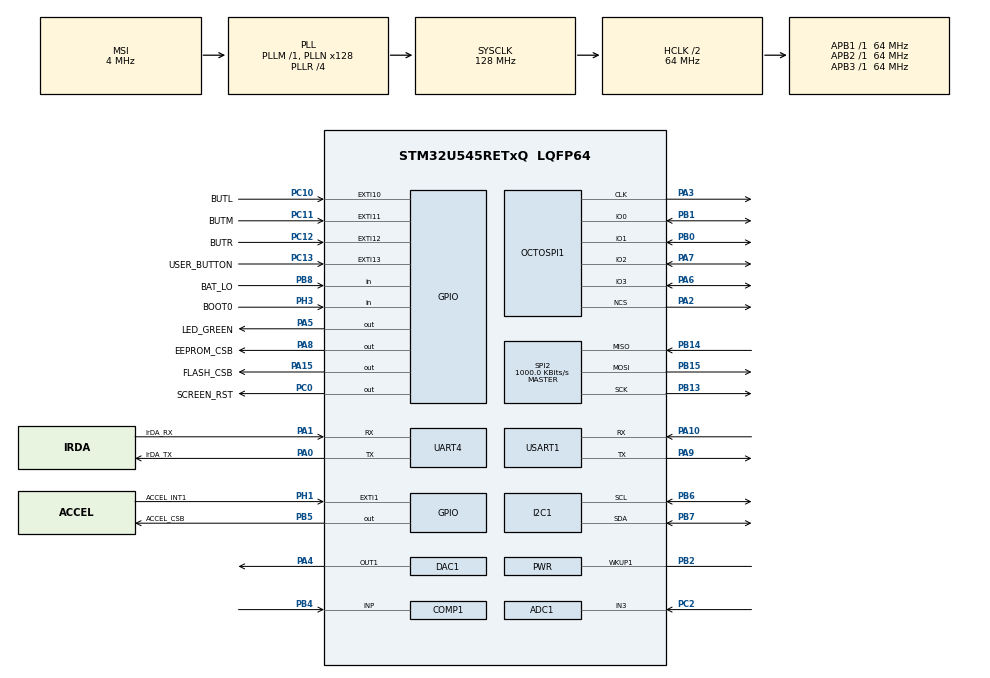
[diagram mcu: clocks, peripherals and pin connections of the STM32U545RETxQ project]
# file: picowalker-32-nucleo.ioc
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ADC1.Channel-1\#ChannelRegularConversion=ADC_CHANNEL_3
ADC1.MonitoredBy-1\#ChannelRegularConversion=__NULL
ADC1.NbrOfConversionFlag=1
ADC1.OffsetNumber-1\#ChannelRegularConversion=ADC_OFFSET_NONE
ADC1.Rank-1\#ChannelRegularConversion=1
ADC1.SamplingTime-1\#ChannelRegularConversion=ADC_SAMPLETIME_5CYCLE
ADC1.master=1
CORTEX_M33_NS.userName=CORTEX_M33
DAC1.DAC_Channel-DAC_OUT1=DAC_CHANNEL_1
I2C1.Timing=0x10707DBC
Mcu.Family=STM32U5
Mcu.Name=STM32U545RETxQ
Mcu.Package=LQFP64
NVIC.EXTI10_IRQn=true\:0\:0\:false\:false\:true\:true\:true\:true
NVIC.EXTI11_IRQn=true\:0\:0\:false\:false\:true\:true\:true\:true
NVIC.EXTI12_IRQn=true\:0\:0\:false\:false\:true\:true\:true\:true
NVIC.EXTI13_IRQn=true\:0\:0\:false\:false\:true\:true\:true\:true
NVIC.EXTI1_IRQn=true\:0\:0\:false\:false\:true\:true\:true\:true
NVIC.PriorityGroup=NVIC_PRIORITYGROUP_4
OCTOSPI1.ClockPrescaler=16
OCTOSPI1.DeviceSize=22
OCTOSPI1.FifoThreshold=8
PA0.GPIO_Label=IrDA_TX
PA0.Mode=Asynchronous
PA0.Signal=UART4_TX
PA1.GPIO_Label=IrDA_RX
PA1.Mode=Asynchronous
PA1.Signal=UART4_RX
PA10.Mode=Asynchronous
PA10.Signal=USART1_RX
PA13\ (JTMS/SWDIO).Mode=Trace_Asynchronous_SW
PA13\ (JTMS/SWDIO).Signal=DEBUG_JTMS-SWDIO
PA14\ (JTCK/SWCLK).Mode=Trace_Asynchronous_SW
PA14\ (JTCK/SWCLK).Signal=DEBUG_JTCK-SWCLK
PA15\ (JTDI).GPIO_Label=FLASH_CSB
PA15\ (JTDI).Signal=GPIO_Output
PA2.Mode=quad_mode
PA2.Signal=OCTOSPI1_NCS
PA3.GPIO_Mode=GPIO_MODE_AF_PP
PA3.GPIO_PuPd=GPIO_NOPULL
PA3.GPIO_Speed_High_Default=GPIO_SPEED_FREQ_VERY_HIGH
PA3.Mode=quad_mode
PA3.Signal=OCTOSPI1_CLK
PA4.Signal=COMP_DAC11_group
PA5.GPIO_Label=LED_GREEN
PA5.GPIO_PuPd=GPIO_PULLUP
PA5.GPIO_Speed=GPIO_SPEED_FREQ_HIGH
PA5.Signal=GPIO_Output
PA6.Mode=quad_mode
PA6.Signal=OCTOSPI1_IO3
PA7.Mode=quad_mode
PA7.Signal=OCTOSPI1_IO2
PA8.GPIO_Label=EEPROM_CSB
PA8.Signal=GPIO_Output
PA9.GPIO_PuPd=GPIO_PULLDOWN
PA9.Mode=Asynchronous
PA9.Signal=USART1_TX
PB0.Mode=quad_mode
PB0.Signal=OCTOSPI1_IO1
PB1.Mode=quad_mode
PB1.Signal=OCTOSPI1_IO0
PB13.Mode=Full_Duplex_Master
PB13.Signal=SPI2_SCK
PB14.Mode=Full_Duplex_Master
PB14.Signal=SPI2_MISO
PB15.GPIO_Mode=GPIO_MODE_AF_PP
PB15.GPIO_PuPd=GPIO_NOPULL
PB15.GPIO_Speed=GPIO_SPEED_FREQ_LOW
PB15.Mode=Full_Duplex_Master
PB15.Signal=SPI2_MOSI
PB2.Mode=WakeUp1
PB2.Signal=PWR_WKUP1
PB3\ (JTDO/TRACESWO).Mode=Trace_Asynchronous_SW
PB3\ (JTDO/TRACESWO).Signal=DEBUG_JTDO-SWO
PB4\ (NJTRST).Mode=INP
PB4\ (NJTRST).Signal=COMP1_INP
PB5.GPIO_Label=ACCEL_CSB
PB5.Signal=GPIO_Output
PB6.Mode=I2C
PB6.Signal=I2C1_SCL
PB7.Mode=I2C
PB7.Signal=I2C1_SDA
PB8.GPIO_Label=BAT_LO
PB8.Signal=GPIO_Input
PC0.GPIO_Label=SCREEN_RST
PC0.Signal=GPIO_Output
PC10.GPIO_Label=BUTL
PC10.GPIO_ModeDefaultEXTI=GPIO_MODE_IT_FALLING
PC10.Signal=GPXTI10
PC11.GPIO_Label=BUTM
PC11.GPIO_ModeDefaultEXTI=GPIO_MODE_IT_FALLING
PC11.Signal=GPXTI11
PC12.GPIO_Label=BUTR
PC12.GPIO_ModeDefaultEXTI=GPIO_MODE_IT_FALLING
PC12.Signal=GPXTI12
PC13.GPIO_Label=USER_BUTTON
PC13.GPIO_ModeDefaultEXTI=GPIO_MODE_IT_FALLING
PC13.Signal=GPXTI13
PC14-OSC32_IN\ (PC14).Mode=LSE-External-Oscillator
PC14-OSC32_IN\ (PC14).Signal=RCC_OSC32_IN
PC15-OSC32_OUT\ (PC15).Mode=LSE-External-Oscillator
PC15-OSC32_OUT\ (PC15).Signal=RCC_OSC32_OUT
PC2.Mode=IN3-Single-Ended
PC2.Signal=ADC1_IN3
PH1-OSC_OUT\ (PH1).GPIO_Label=ACCEL_INT1
PH1-OSC_OUT\ (PH1).GPIO_ModeDefaultEXTI=GPIO_MODE_IT_FALLING
PH1-OSC_OUT\ (PH1).Signal=GPXTI1
PH3-BOOT0.GPIO_Label=BOOT0
PH3-BOOT0.Signal=GPIO_Input
PWR.PowerMode=PWR_SMPS_SUPPLY
ProjectManager.HeapSize=0x200
ProjectManager.StackSize=0x400
ProjectManager.TargetToolchain=Makefile
RCC.ADCFreq_Value=16000000
RCC.AHBCLKDivider=RCC_SYSCLK_DIV2
RCC.AHBFreq_Value=64000000
RCC.APB1Freq_Value=64000000
RCC.APB1TimFreq_Value=64000000
RCC.APB2Freq_Value=64000000
RCC.APB2TimFreq_Value=64000000
RCC.APB3Freq_Value=64000000
RCC.CortexFreq_Value=64000000
RCC.DACCLockSelectionVirtual=RCC_DAC1CLKSOURCE_LSI
RCC.DACCLockSelectionVirtualString=RCC_DAC1CLKSOURCE_LSI
RCC.EPOD_VALUE=4000000
RCC.HCLKFreq_Value=64000000
RCC.HSE_VALUE=16000000
RCC.HSI48_VALUE=48000000
RCC.HSI_VALUE=16000000
RCC.LSIDIV_VALUE=32000
RCC.MSI_VALUE=4000000
RCC.PLL1R=4
RCC.PLLN=128
RCC.SYSCLKFreq_VALUE=128000000
RCC.SYSCLKSource=RCC_SYSCLKSOURCE_PLLCLK
RCC.USBFreq_Value=48000000
RCC.VCOOutputFreq_Value=512000000
SH.COMP_DAC11_group.0=DAC1_OUT1,DAC_OUT1
SPI2.BaudRatePrescaler=SPI_BAUDRATEPRESCALER_128
SPI2.CalculateBaudRate=1000.0 KBits/s
SPI2.DataSize=SPI_DATASIZE_8BIT
SPI2.Direction=SPI_DIRECTION_2LINES
SPI2.MasterKeepIOState=SPI_MASTER_KEEP_IO_STATE_ENABLE
SPI2.MasterSSIdleness=SPI_MASTER_SS_IDLENESS_00CYCLE
SPI2.Mode=SPI_MODE_MASTER
SPI2.NSSPMode=SPI_NSS_PULSE_DISABLE
SPI2.VirtualType=VM_MASTER
TIM1.AutoReloadPreload=TIM_AUTORELOAD_PRELOAD_ENABLE
TIM1.Prescaler=63
UART4.AutonomousMode=AUTONOMOUS_MODE_DISABLE
UART4.MSBFirstParam=UART_ADVFEATURE_MSBFIRST_DISABLE
USART1.VirtualMode-Asynchronous=VM_ASYNC
VP_COMP1_VS_VREFINT.Mode=VREFINT
VP_ICACHE_VS_ICACHE.Mode=DirectMappedCache
VP_LPBAMQUEUE_VS_QUEUE.Mode=QUEUEMODE
VP_MEMORYMAP_VS_MEMORYMAP.Mode=CurAppReg
VP_PWR_VS_DBSignals.Mode=DisableDeadBatterySignals
VP_PWR_VS_LPOM.Mode=PowerOptimisation
VP_PWR_VS_SECSignals.Mode=Security/Privilege
VP_PWR_Vdda.Mode=isolationVdda
VP_TIM1_VS_ClockSourceINT.Mode=Internal
board=NUCLEO-U545RE-Q

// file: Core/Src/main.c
/* USER CODE BEGIN Header */
/**
  ******************************************************************************
  * @file           : main.c
  * @brief          : Main program body
  ******************************************************************************
  * @attention
  *
  * Copyright (c) 2024 STMicroelectronics.
  * All rights reserved.
  *
  * This software is licensed under terms that can be found in the LICENSE file
  * in the root directory of this software component.
  * If no LICENSE file comes with this software, it is provided AS-IS.
  *
  ******************************************************************************
  */
/* USER CODE END Header */
#include "main.h"

/* USER CODE BEGIN Includes */

extern void picowalker_main();

/* USER CODE END Includes */

ADC_HandleTypeDef hadc1;

COMP_HandleTypeDef hcomp1;

DAC_HandleTypeDef hdac1;

I2C_HandleTypeDef hi2c1;

OSPI_HandleTypeDef hospi1;

SPI_HandleTypeDef hspi2;

TIM_HandleTypeDef htim1;

UART_HandleTypeDef huart4;
UART_HandleTypeDef huart1;

void SystemClock_Config(void);
static void SystemPower_Config(void);
static void MX_GPIO_Init(void);
static void MX_ADC1_Init(void);
static void MX_COMP1_Init(void);
static void MX_I2C1_Init(void);
static void MX_ICACHE_Init(void);
static void MX_OCTOSPI1_Init(void);
static void MX_SPI2_Init(void);
static void MX_USART1_UART_Init(void);
static void MX_DAC1_Init(void);
static void MX_UART4_Init(void);
static void MX_TIM1_Init(void);

int main(void)
{

  /* MCU Configuration--------------------------------------------------------*/

  /* Reset of all peripherals, Initializes the Flash interface and the Systick. */
  HAL_Init();

  /* Configure the system clock */
  SystemClock_Config();

  /* Configure the System Power */
  SystemPower_Config();

  /* Initialize all configured peripherals */
  MX_GPIO_Init();
  MX_ADC1_Init();
  MX_COMP1_Init();
  MX_I2C1_Init();
  MX_ICACHE_Init();
  MX_OCTOSPI1_Init();
  MX_SPI2_Init();
  MX_USART1_UART_Init();
  MX_DAC1_Init();
  MX_UART4_Init();
  MX_TIM1_Init();
  /* USER CODE BEGIN 2 */

  picowalker_main();

  /* USER CODE END 2 */

  /* Infinite loop */
  while (1)
  {

  }
}

void SystemClock_Config(void)
{
  RCC_OscInitTypeDef RCC_OscInitStruct = {0};
  RCC_ClkInitTypeDef RCC_ClkInitStruct = {0};

  /** Configure the main internal regulator output voltage
  */
  if (HAL_PWREx_ControlVoltageScaling(PWR_REGULATOR_VOLTAGE_SCALE1) != HAL_OK)
  {
    Error_Handler();
  }

  /** Initializes the CPU, AHB and APB buses clocks
  */
  RCC_OscInitStruct.OscillatorType = RCC_OSCILLATORTYPE_HSI|RCC_OSCILLATORTYPE_LSI
                              |RCC_OSCILLATORTYPE_MSI;
  RCC_OscInitStruct.HSIState = RCC_HSI_ON;
  RCC_OscInitStruct.HSICalibrationValue = RCC_HSICALIBRATION_DEFAULT;
  RCC_OscInitStruct.LSIState = RCC_LSI_ON;
  RCC_OscInitStruct.MSIState = RCC_MSI_ON;
  RCC_OscInitStruct.MSICalibrationValue = RCC_MSICALIBRATION_DEFAULT;
  RCC_OscInitStruct.MSIClockRange = RCC_MSIRANGE_4;
  RCC_OscInitStruct.LSIDiv = RCC_LSI_DIV1;
  RCC_OscInitStruct.PLL.PLLState = RCC_PLL_ON;
  RCC_OscInitStruct.PLL.PLLSource = RCC_PLLSOURCE_MSI;
  RCC_OscInitStruct.PLL.PLLMBOOST = RCC_PLLMBOOST_DIV1;
  RCC_OscInitStruct.PLL.PLLM = 1;
  RCC_OscInitStruct.PLL.PLLN = 128;
  RCC_OscInitStruct.PLL.PLLP = 2;
  RCC_OscInitStruct.PLL.PLLQ = 2;
  RCC_OscInitStruct.PLL.PLLR = 4;
  RCC_OscInitStruct.PLL.PLLRGE = RCC_PLLVCIRANGE_0;
  RCC_OscInitStruct.PLL.PLLFRACN = 0;
  if (HAL_RCC_OscConfig(&RCC_OscInitStruct) != HAL_OK)
  {
    Error_Handler();
  }

  /** Initializes the CPU, AHB and APB buses clocks
  */
  RCC_ClkInitStruct.ClockType = RCC_CLOCKTYPE_HCLK|RCC_CLOCKTYPE_SYSCLK
                              |RCC_CLOCKTYPE_PCLK1|RCC_CLOCKTYPE_PCLK2
                              |RCC_CLOCKTYPE_PCLK3;
  RCC_ClkInitStruct.SYSCLKSource = RCC_SYSCLKSOURCE_PLLCLK;
  RCC_ClkInitStruct.AHBCLKDivider = RCC_SYSCLK_DIV2;
  RCC_ClkInitStruct.APB1CLKDivider = RCC_HCLK_DIV1;
  RCC_ClkInitStruct.APB2CLKDivider = RCC_HCLK_DIV1;
  RCC_ClkInitStruct.APB3CLKDivider = RCC_HCLK_DIV1;

  if (HAL_RCC_ClockConfig(&RCC_ClkInitStruct, FLASH_LATENCY_1) != HAL_OK)
  {
    Error_Handler();
  }
}

/**
  * @brief Power Configuration
  * @retval None
  */
static void SystemPower_Config(void)
{

  /*
   * Switch to SMPS regulator instead of LDO
   */
  if (HAL_PWREx_ConfigSupply(PWR_SMPS_SUPPLY) != HAL_OK)
  {
    Error_Handler();
  }
}

static void MX_ADC1_Init(void)
{

  ADC_ChannelConfTypeDef sConfig = {0};

  /** Common config
  */
  hadc1.Instance = ADC1;
  hadc1.Init.ClockPrescaler = ADC_CLOCK_ASYNC_DIV1;
  hadc1.Init.Resolution = ADC_RESOLUTION_14B;
  hadc1.Init.GainCompensation = 0;
  hadc1.Init.DataAlign = ADC_DATAALIGN_RIGHT;
  hadc1.Init.ScanConvMode = ADC_SCAN_DISABLE;
  hadc1.Init.EOCSelection = ADC_EOC_SINGLE_CONV;
  hadc1.Init.LowPowerAutoWait = DISABLE;
  hadc1.Init.ContinuousConvMode = DISABLE;
  hadc1.Init.NbrOfConversion = 1;
  hadc1.Init.DiscontinuousConvMode = DISABLE;
  hadc1.Init.ExternalTrigConv = ADC_SOFTWARE_START;
  hadc1.Init.ExternalTrigConvEdge = ADC_EXTERNALTRIGCONVEDGE_NONE;
  hadc1.Init.DMAContinuousRequests = DISABLE;
  hadc1.Init.TriggerFrequencyMode = ADC_TRIGGER_FREQ_HIGH;
  hadc1.Init.Overrun = ADC_OVR_DATA_PRESERVED;
  hadc1.Init.LeftBitShift = ADC_LEFTBITSHIFT_NONE;
  hadc1.Init.ConversionDataManagement = ADC_CONVERSIONDATA_DR;
  hadc1.Init.OversamplingMode = DISABLE;
  if (HAL_ADC_Init(&hadc1) != HAL_OK)
  {
    Error_Handler();
  }

  /** Configure Regular Channel
  */
  sConfig.Channel = ADC_CHANNEL_3;
  sConfig.Rank = ADC_REGULAR_RANK_1;
  sConfig.SamplingTime = ADC_SAMPLETIME_5CYCLE;
  sConfig.SingleDiff = ADC_SINGLE_ENDED;
  sConfig.OffsetNumber = ADC_OFFSET_NONE;
  sConfig.Offset = 0;
  if (HAL_ADC_ConfigChannel(&hadc1, &sConfig) != HAL_OK)
  {
    Error_Handler();
  }

}

static void MX_COMP1_Init(void)
{

  hcomp1.Instance = COMP1;
  hcomp1.Init.InputMinus = COMP_INPUT_MINUS_VREFINT;
  hcomp1.Init.OutputPol = COMP_OUTPUTPOL_NONINVERTED;
  hcomp1.Init.Hysteresis = COMP_HYSTERESIS_NONE;
  hcomp1.Init.BlankingSrce = COMP_BLANKINGSRC_NONE;
  hcomp1.Init.Mode = COMP_POWERMODE_HIGHSPEED;
  hcomp1.Init.TriggerMode = COMP_TRIGGERMODE_NONE;
  if (HAL_COMP_Init(&hcomp1) != HAL_OK)
  {
    Error_Handler();
  }

}

static void MX_DAC1_Init(void)
{

  DAC_ChannelConfTypeDef sConfig = {0};
  DAC_AutonomousModeConfTypeDef sAutonomousMode = {0};

  /** DAC Initialization
  */
  hdac1.Instance = DAC1;
  if (HAL_DAC_Init(&hdac1) != HAL_OK)
  {
    Error_Handler();
  }

  /** DAC channel OUT1 config
  */
  sConfig.DAC_HighFrequency = DAC_HIGH_FREQUENCY_INTERFACE_MODE_DISABLE;
  sConfig.DAC_DMADoubleDataMode = DISABLE;
  sConfig.DAC_SignedFormat = DISABLE;
  sConfig.DAC_SampleAndHold = DAC_SAMPLEANDHOLD_DISABLE;
  sConfig.DAC_Trigger = DAC_TRIGGER_NONE;
  sConfig.DAC_OutputBuffer = DAC_OUTPUTBUFFER_DISABLE;
  sConfig.DAC_ConnectOnChipPeripheral = DAC_CHIPCONNECT_EXTERNAL;
  sConfig.DAC_UserTrimming = DAC_TRIMMING_FACTORY;
  if (HAL_DAC_ConfigChannel(&hdac1, &sConfig, DAC_CHANNEL_1) != HAL_OK)
  {
    Error_Handler();
  }

  /** Configure Autonomous Mode
  */
  sAutonomousMode.AutonomousModeState = DAC_AUTONOMOUS_MODE_DISABLE;
  if (HAL_DACEx_SetConfigAutonomousMode(&hdac1, &sAutonomousMode) != HAL_OK)
  {
    Error_Handler();
  }

}

static void MX_I2C1_Init(void)
{

  hi2c1.Instance = I2C1;
  hi2c1.Init.Timing = 0x10707DBC;
  hi2c1.Init.OwnAddress1 = 0;
  hi2c1.Init.AddressingMode = I2C_ADDRESSINGMODE_7BIT;
  hi2c1.Init.DualAddressMode = I2C_DUALADDRESS_DISABLE;
  hi2c1.Init.OwnAddress2 = 0;
  hi2c1.Init.OwnAddress2Masks = I2C_OA2_NOMASK;
  hi2c1.Init.GeneralCallMode = I2C_GENERALCALL_DISABLE;
  hi2c1.Init.NoStretchMode = I2C_NOSTRETCH_DISABLE;
  if (HAL_I2C_Init(&hi2c1) != HAL_OK)
  {
    Error_Handler();
  }

  /** Configure Analogue filter
  */
  if (HAL_I2CEx_ConfigAnalogFilter(&hi2c1, I2C_ANALOGFILTER_ENABLE) != HAL_OK)
  {
    Error_Handler();
  }

  /** Configure Digital filter
  */
  if (HAL_I2CEx_ConfigDigitalFilter(&hi2c1, 0) != HAL_OK)
  {
    Error_Handler();
  }

}

static void MX_ICACHE_Init(void)
{

  /** Enable instruction cache in 1-way (direct mapped cache)
  */
  if (HAL_ICACHE_ConfigAssociativityMode(ICACHE_1WAY) != HAL_OK)
  {
    Error_Handler();
  }
  if (HAL_ICACHE_Enable() != HAL_OK)
  {
    Error_Handler();
  }

}

static void MX_OCTOSPI1_Init(void)
{

  /* OCTOSPI1 parameter configuration*/
  hospi1.Instance = OCTOSPI1;
  hospi1.Init.FifoThreshold = 8;
  hospi1.Init.DualQuad = HAL_OSPI_DUALQUAD_DISABLE;
  hospi1.Init.MemoryType = HAL_OSPI_MEMTYPE_MICRON;
  hospi1.Init.DeviceSize = 22;
  hospi1.Init.ChipSelectHighTime = 1;
  hospi1.Init.FreeRunningClock = HAL_OSPI_FREERUNCLK_DISABLE;
  hospi1.Init.ClockMode = HAL_OSPI_CLOCK_MODE_0;
  hospi1.Init.WrapSize = HAL_OSPI_WRAP_NOT_SUPPORTED;
  hospi1.Init.ClockPrescaler = 16;
  hospi1.Init.SampleShifting = HAL_OSPI_SAMPLE_SHIFTING_NONE;
  hospi1.Init.DelayHoldQuarterCycle = HAL_OSPI_DHQC_DISABLE;
  hospi1.Init.ChipSelectBoundary = 0;
  hospi1.Init.MaxTran = 0;
  hospi1.Init.Refresh = 0;
  if (HAL_OSPI_Init(&hospi1) != HAL_OK)
  {
    Error_Handler();
  }

}

static void MX_SPI2_Init(void)
{

  SPI_AutonomousModeConfTypeDef HAL_SPI_AutonomousMode_Cfg_Struct = {0};

  /* SPI2 parameter configuration*/
  hspi2.Instance = SPI2;
  hspi2.Init.Mode = SPI_MODE_MASTER;
  hspi2.Init.Direction = SPI_DIRECTION_2LINES;
  hspi2.Init.DataSize = SPI_DATASIZE_8BIT;
  hspi2.Init.CLKPolarity = SPI_POLARITY_LOW;
  hspi2.Init.CLKPhase = SPI_PHASE_1EDGE;
  hspi2.Init.NSS = SPI_NSS_SOFT;
  hspi2.Init.BaudRatePrescaler = SPI_BAUDRATEPRESCALER_128;
  hspi2.Init.FirstBit = SPI_FIRSTBIT_MSB;
  hspi2.Init.TIMode = SPI_TIMODE_DISABLE;
  hspi2.Init.CRCCalculation = SPI_CRCCALCULATION_DISABLE;
  hspi2.Init.CRCPolynomial = 0x7;
  hspi2.Init.NSSPMode = SPI_NSS_PULSE_DISABLE;
  hspi2.Init.NSSPolarity = SPI_NSS_POLARITY_LOW;
  hspi2.Init.FifoThreshold = SPI_FIFO_THRESHOLD_01DATA;
  hspi2.Init.MasterSSIdleness = SPI_MASTER_SS_IDLENESS_00CYCLE;
  hspi2.Init.MasterInterDataIdleness = SPI_MASTER_INTERDATA_IDLENESS_00CYCLE;
  hspi2.Init.MasterReceiverAutoSusp = SPI_MASTER_RX_AUTOSUSP_DISABLE;
  hspi2.Init.MasterKeepIOState = SPI_MASTER_KEEP_IO_STATE_ENABLE;
  hspi2.Init.IOSwap = SPI_IO_SWAP_DISABLE;
  hspi2.Init.ReadyMasterManagement = SPI_RDY_MASTER_MANAGEMENT_INTERNALLY;
  hspi2.Init.ReadyPolarity = SPI_RDY_POLARITY_HIGH;
  if (HAL_SPI_Init(&hspi2) != HAL_OK)
  {
    Error_Handler();
  }
  HAL_SPI_AutonomousMode_Cfg_Struct.TriggerState = SPI_AUTO_MODE_DISABLE;
  HAL_SPI_AutonomousMode_Cfg_Struct.TriggerSelection = SPI_GRP1_GPDMA_CH0_TCF_TRG;
  HAL_SPI_AutonomousMode_Cfg_Struct.TriggerPolarity = SPI_TRIG_POLARITY_RISING;
  if (HAL_SPIEx_SetConfigAutonomousMode(&hspi2, &HAL_SPI_AutonomousMode_Cfg_Struct) != HAL_OK)
  {
    Error_Handler();
  }

}

static void MX_TIM1_Init(void)
{

  TIM_ClockConfigTypeDef sClockSourceConfig = {0};
  TIM_MasterConfigTypeDef sMasterConfig = {0};

  htim1.Instance = TIM1;
  htim1.Init.Prescaler = 63;
  htim1.Init.CounterMode = TIM_COUNTERMODE_UP;
  htim1.Init.Period = 65535;
  htim1.Init.ClockDivision = TIM_CLOCKDIVISION_DIV1;
  htim1.Init.RepetitionCounter = 0;
  htim1.Init.AutoReloadPreload = TIM_AUTORELOAD_PRELOAD_ENABLE;
  if (HAL_TIM_Base_Init(&htim1) != HAL_OK)
  {
    Error_Handler();
  }
  sClockSourceConfig.ClockSource = TIM_CLOCKSOURCE_INTERNAL;
  if (HAL_TIM_ConfigClockSource(&htim1, &sClockSourceConfig) != HAL_OK)
  {
    Error_Handler();
  }
  sMasterConfig.MasterOutputTrigger = TIM_TRGO_RESET;
  sMasterConfig.MasterOutputTrigger2 = TIM_TRGO2_RESET;
  sMasterConfig.MasterSlaveMode = TIM_MASTERSLAVEMODE_DISABLE;
  if (HAL_TIMEx_MasterConfigSynchronization(&htim1, &sMasterConfig) != HAL_OK)
  {
    Error_Handler();
  }

}

static void MX_UART4_Init(void)
{

  huart4.Instance = UART4;
  huart4.Init.BaudRate = 115200;
  huart4.Init.WordLength = UART_WORDLENGTH_8B;
  huart4.Init.StopBits = UART_STOPBITS_1;
  huart4.Init.Parity = UART_PARITY_NONE;
  huart4.Init.Mode = UART_MODE_TX_RX;
  huart4.Init.HwFlowCtl = UART_HWCONTROL_NONE;
  huart4.Init.OverSampling = UART_OVERSAMPLING_16;
  huart4.Init.OneBitSampling = UART_ONE_BIT_SAMPLE_DISABLE;
  huart4.Init.ClockPrescaler = UART_PRESCALER_DIV1;
  huart4.AdvancedInit.AdvFeatureInit = UART_ADVFEATURE_NO_INIT;
  if (HAL_UART_Init(&huart4) != HAL_OK)
  {
    Error_Handler();
  }
  if (HAL_UARTEx_SetTxFifoThreshold(&huart4, UART_TXFIFO_THRESHOLD_1_8) != HAL_OK)
  {
    Error_Handler();
  }
  if (HAL_UARTEx_SetRxFifoThreshold(&huart4, UART_RXFIFO_THRESHOLD_1_8) != HAL_OK)
  {
    Error_Handler();
  }
  if (HAL_UARTEx_DisableFifoMode(&huart4) != HAL_OK)
  {
    Error_Handler();
  }

}

static void MX_USART1_UART_Init(void)
{

  huart1.Instance = USART1;
  huart1.Init.BaudRate = 115200;
  huart1.Init.WordLength = UART_WORDLENGTH_8B;
  huart1.Init.StopBits = UART_STOPBITS_1;
  huart1.Init.Parity = UART_PARITY_NONE;
  huart1.Init.Mode = UART_MODE_TX_RX;
  huart1.Init.HwFlowCtl = UART_HWCONTROL_NONE;
  huart1.Init.OverSampling = UART_OVERSAMPLING_16;
  huart1.Init.OneBitSampling = UART_ONE_BIT_SAMPLE_DISABLE;
  huart1.Init.ClockPrescaler = UART_PRESCALER_DIV1;
  huart1.AdvancedInit.AdvFeatureInit = UART_ADVFEATURE_NO_INIT;
  if (HAL_UART_Init(&huart1) != HAL_OK)
  {
    Error_Handler();
  }
  if (HAL_UARTEx_SetTxFifoThreshold(&huart1, UART_TXFIFO_THRESHOLD_1_8) != HAL_OK)
  {
    Error_Handler();
  }
  if (HAL_UARTEx_SetRxFifoThreshold(&huart1, UART_RXFIFO_THRESHOLD_1_8) != HAL_OK)
  {
    Error_Handler();
  }
  if (HAL_UARTEx_DisableFifoMode(&huart1) != HAL_OK)
  {
    Error_Handler();
  }

}

static void MX_GPIO_Init(void)
{
  GPIO_InitTypeDef GPIO_InitStruct = {0};

  /* GPIO Ports Clock Enable */
  __HAL_RCC_GPIOC_CLK_ENABLE();
  __HAL_RCC_GPIOH_CLK_ENABLE();
  __HAL_RCC_GPIOA_CLK_ENABLE();
  __HAL_RCC_GPIOB_CLK_ENABLE();

  /*Configure GPIO pin Output Level */
  HAL_GPIO_WritePin(SCREEN_RST_GPIO_Port, SCREEN_RST_Pin, GPIO_PIN_RESET);

  /*Configure GPIO pin Output Level */
  HAL_GPIO_WritePin(GPIOA, LED_GREEN_Pin|EEPROM_CSB_Pin|FLASH_CSB_Pin, GPIO_PIN_RESET);

  /*Configure GPIO pin Output Level */
  HAL_GPIO_WritePin(ACCEL_CSB_GPIO_Port, ACCEL_CSB_Pin, GPIO_PIN_RESET);

  /*Configure GPIO pins : USER_BUTTON_Pin BUTL_Pin BUTM_Pin BUTR_Pin */
  GPIO_InitStruct.Pin = USER_BUTTON_Pin|BUTL_Pin|BUTM_Pin|BUTR_Pin;
  GPIO_InitStruct.Mode = GPIO_MODE_IT_FALLING;
  GPIO_InitStruct.Pull = GPIO_NOPULL;
  HAL_GPIO_Init(GPIOC, &GPIO_InitStruct);

  /*Configure GPIO pin : ACCEL_INT1_Pin */
  GPIO_InitStruct.Pin = ACCEL_INT1_Pin;
  GPIO_InitStruct.Mode = GPIO_MODE_IT_FALLING;
  GPIO_InitStruct.Pull = GPIO_NOPULL;
  HAL_GPIO_Init(ACCEL_INT1_GPIO_Port, &GPIO_InitStruct);

  /*Configure GPIO pin : SCREEN_RST_Pin */
  GPIO_InitStruct.Pin = SCREEN_RST_Pin;
  GPIO_InitStruct.Mode = GPIO_MODE_OUTPUT_PP;
  GPIO_InitStruct.Pull = GPIO_NOPULL;
  GPIO_InitStruct.Speed = GPIO_SPEED_FREQ_LOW;
  HAL_GPIO_Init(SCREEN_RST_GPIO_Port, &GPIO_InitStruct);

  /*Configure GPIO pin : LED_GREEN_Pin */
  GPIO_InitStruct.Pin = LED_GREEN_Pin;
  GPIO_InitStruct.Mode = GPIO_MODE_OUTPUT_PP;
  GPIO_InitStruct.Pull = GPIO_PULLUP;
  GPIO_InitStruct.Speed = GPIO_SPEED_FREQ_HIGH;
  HAL_GPIO_Init(LED_GREEN_GPIO_Port, &GPIO_InitStruct);

  /*Configure GPIO pins : EEPROM_CSB_Pin FLASH_CSB_Pin */
  GPIO_InitStruct.Pin = EEPROM_CSB_Pin|FLASH_CSB_Pin;
  GPIO_InitStruct.Mode = GPIO_MODE_OUTPUT_PP;
  GPIO_InitStruct.Pull = GPIO_NOPULL;
  GPIO_InitStruct.Speed = GPIO_SPEED_FREQ_LOW;
  HAL_GPIO_Init(GPIOA, &GPIO_InitStruct);

  /*Configure GPIO pin : ACCEL_CSB_Pin */
  GPIO_InitStruct.Pin = ACCEL_CSB_Pin;
  GPIO_InitStruct.Mode = GPIO_MODE_OUTPUT_PP;
  GPIO_InitStruct.Pull = GPIO_NOPULL;
  GPIO_InitStruct.Speed = GPIO_SPEED_FREQ_LOW;
  HAL_GPIO_Init(ACCEL_CSB_GPIO_Port, &GPIO_InitStruct);

  /*Configure GPIO pin : BOOT0_Pin */
  GPIO_InitStruct.Pin = BOOT0_Pin;
  GPIO_InitStruct.Mode = GPIO_MODE_INPUT;
  GPIO_InitStruct.Pull = GPIO_NOPULL;
  HAL_GPIO_Init(BOOT0_GPIO_Port, &GPIO_InitStruct);

  /*Configure GPIO pin : BAT_LO_Pin */
  GPIO_InitStruct.Pin = BAT_LO_Pin;
  GPIO_InitStruct.Mode = GPIO_MODE_INPUT;
  GPIO_InitStruct.Pull = GPIO_NOPULL;
  HAL_GPIO_Init(BAT_LO_GPIO_Port, &GPIO_InitStruct);

  /* EXTI interrupt init*/
  HAL_NVIC_SetPriority(EXTI1_IRQn, 0, 0);
  HAL_NVIC_EnableIRQ(EXTI1_IRQn);

  HAL_NVIC_SetPriority(EXTI10_IRQn, 0, 0);
  HAL_NVIC_EnableIRQ(EXTI10_IRQn);

  HAL_NVIC_SetPriority(EXTI11_IRQn, 0, 0);
  HAL_NVIC_EnableIRQ(EXTI11_IRQn);

  HAL_NVIC_SetPriority(EXTI12_IRQn, 0, 0);
  HAL_NVIC_EnableIRQ(EXTI12_IRQn);

  HAL_NVIC_SetPriority(EXTI13_IRQn, 0, 0);
  HAL_NVIC_EnableIRQ(EXTI13_IRQn);

}

void Error_Handler(void)
{
  __disable_irq();
  while (1)
  {
  }
}
